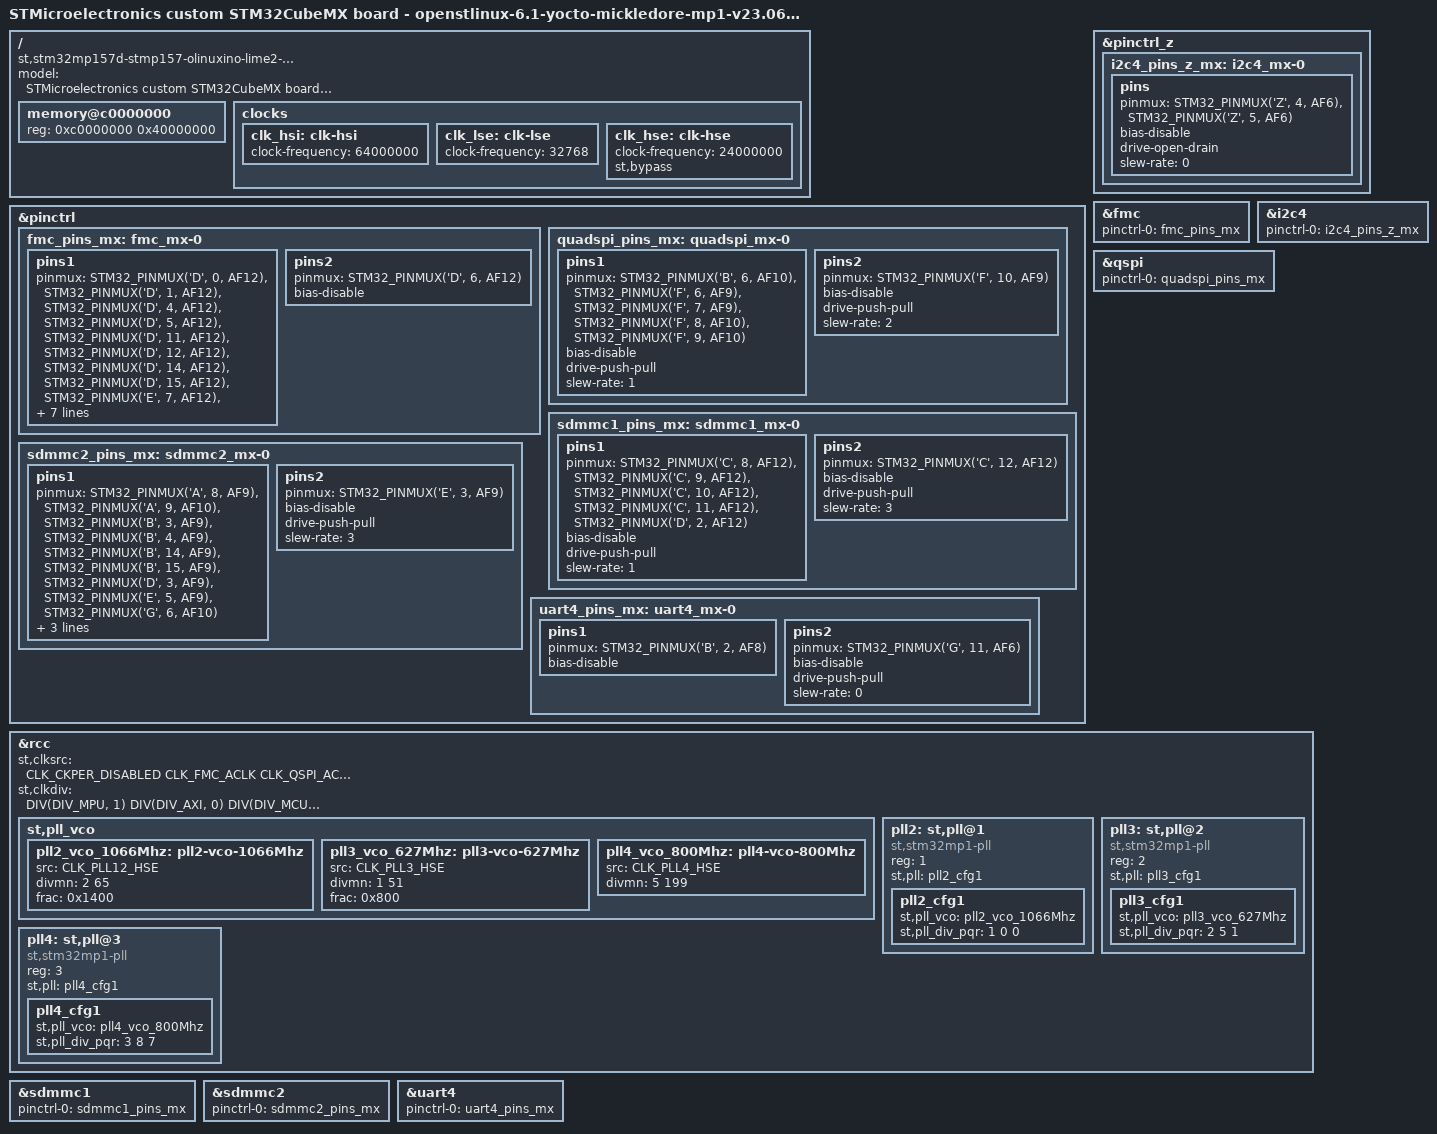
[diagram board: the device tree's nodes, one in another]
// SPDX-License-Identifier: (GPL-2.0-or-later OR BSD-3-Clause)
/*
 * Copyright (C) 2023, STMicroelectronics - All Rights Reserved
 * Author: STM32CubeMX code generation for STMicroelectronics.
 */

/* For more information on Device Tree configuration, please refer to
 * https://wiki.st.com/stm32mpu/wiki/Category:Device_tree_configuration
 */

/dts-v1/;
#include <dt-bindings/pinctrl/stm32-pinfunc.h>
#include <dt-bindings/clock/stm32mp1-clksrc.h>
#include "stm32mp15-mx.dtsi"

#include "stm32mp157.dtsi"
#include "stm32mp15xd.dtsi"
#include "stm32mp15-pinctrl.dtsi"
#include "stm32mp15xxaa-pinctrl.dtsi"
#include "stm32mp15-ddr.dtsi"

/* USER CODE BEGIN includes */
/* USER CODE END includes */

/ {
	model = "STMicroelectronics custom STM32CubeMX board - openstlinux-6.1-yocto-mickledore-mp1-v23.06.21";
	compatible = "st,stm32mp157d-stmp157-olinuxino-lime2-mx", "st,stm32mp157";

	memory@c0000000 {
		device_type = "memory";
		reg = <0xc0000000 0x40000000>;

		/* USER CODE BEGIN memory */
		/* USER CODE END memory */
	};

	/* USER CODE BEGIN root */
	/* USER CODE END root */

	clocks {
		/* USER CODE BEGIN clocks */
		/* USER CODE END clocks */

		clk_hsi: clk-hsi {
			clock-frequency = <64000000>;

			/* USER CODE BEGIN clk_hsi */
			/* USER CODE END clk_hsi */
		};
		clk_lse: clk-lse {
			clock-frequency = <32768>;

			/* USER CODE BEGIN clk_lse */
			/* USER CODE END clk_lse */
		};
		clk_hse: clk-hse {
			clock-frequency = <24000000>;
			st,bypass;

			/* USER CODE BEGIN clk_hse */
			/* USER CODE END clk_hse */
		};
	};

}; /*root*/

&pinctrl {
	fmc_pins_mx: fmc_mx-0 {
		pins1 {
			pinmux = <STM32_PINMUX('D', 0, AF12)>, /* FMC_D2 */
					 <STM32_PINMUX('D', 1, AF12)>, /* FMC_D3 */
					 <STM32_PINMUX('D', 4, AF12)>, /* FMC_NOE */
					 <STM32_PINMUX('D', 5, AF12)>, /* FMC_NWE */
					 <STM32_PINMUX('D', 11, AF12)>, /* FMC_CLE */
					 <STM32_PINMUX('D', 12, AF12)>, /* FMC_ALE */
					 <STM32_PINMUX('D', 14, AF12)>, /* FMC_D0 */
					 <STM32_PINMUX('D', 15, AF12)>, /* FMC_D1 */
					 <STM32_PINMUX('E', 7, AF12)>, /* FMC_D4 */
					 <STM32_PINMUX('E', 8, AF12)>, /* FMC_D5 */
					 <STM32_PINMUX('E', 9, AF12)>, /* FMC_D6 */
					 <STM32_PINMUX('E', 10, AF12)>, /* FMC_D7 */
					 <STM32_PINMUX('G', 9, AF12)>; /* FMC_NCE */
			bias-disable;
			drive-push-pull;
			slew-rate = <1>;
		};
		pins2 {
			pinmux = <STM32_PINMUX('D', 6, AF12)>; /* FMC_NWAIT */
			bias-disable;
		};
	};

	quadspi_pins_mx: quadspi_mx-0 {
		pins1 {
			pinmux = <STM32_PINMUX('B', 6, AF10)>, /* QUADSPI_BK1_NCS */
					 <STM32_PINMUX('F', 6, AF9)>, /* QUADSPI_BK1_IO3 */
					 <STM32_PINMUX('F', 7, AF9)>, /* QUADSPI_BK1_IO2 */
					 <STM32_PINMUX('F', 8, AF10)>, /* QUADSPI_BK1_IO0 */
					 <STM32_PINMUX('F', 9, AF10)>; /* QUADSPI_BK1_IO1 */
			bias-disable;
			drive-push-pull;
			slew-rate = <1>;
		};
		pins2 {
			pinmux = <STM32_PINMUX('F', 10, AF9)>; /* QUADSPI_CLK */
			bias-disable;
			drive-push-pull;
			slew-rate = <2>;
		};
	};

	sdmmc1_pins_mx: sdmmc1_mx-0 {
		pins1 {
			pinmux = <STM32_PINMUX('C', 8, AF12)>, /* SDMMC1_D0 */
					 <STM32_PINMUX('C', 9, AF12)>, /* SDMMC1_D1 */
					 <STM32_PINMUX('C', 10, AF12)>, /* SDMMC1_D2 */
					 <STM32_PINMUX('C', 11, AF12)>, /* SDMMC1_D3 */
					 <STM32_PINMUX('D', 2, AF12)>; /* SDMMC1_CMD */
			bias-disable;
			drive-push-pull;
			slew-rate = <1>;
		};
		pins2 {
			pinmux = <STM32_PINMUX('C', 12, AF12)>; /* SDMMC1_CK */
			bias-disable;
			drive-push-pull;
			slew-rate = <3>;
		};
	};

	sdmmc2_pins_mx: sdmmc2_mx-0 {
		pins1 {
			pinmux = <STM32_PINMUX('A', 8, AF9)>, /* SDMMC2_D4 */
					 <STM32_PINMUX('A', 9, AF10)>, /* SDMMC2_D5 */
					 <STM32_PINMUX('B', 3, AF9)>, /* SDMMC2_D2 */
					 <STM32_PINMUX('B', 4, AF9)>, /* SDMMC2_D3 */
					 <STM32_PINMUX('B', 14, AF9)>, /* SDMMC2_D0 */
					 <STM32_PINMUX('B', 15, AF9)>, /* SDMMC2_D1 */
					 <STM32_PINMUX('D', 3, AF9)>, /* SDMMC2_D7 */
					 <STM32_PINMUX('E', 5, AF9)>, /* SDMMC2_D6 */
					 <STM32_PINMUX('G', 6, AF10)>; /* SDMMC2_CMD */
			bias-disable;
			drive-push-pull;
			slew-rate = <1>;
		};
		pins2 {
			pinmux = <STM32_PINMUX('E', 3, AF9)>; /* SDMMC2_CK */
			bias-disable;
			drive-push-pull;
			slew-rate = <3>;
		};
	};

	uart4_pins_mx: uart4_mx-0 {
		pins1 {
			pinmux = <STM32_PINMUX('B', 2, AF8)>; /* UART4_RX */
			bias-disable;
		};
		pins2 {
			pinmux = <STM32_PINMUX('G', 11, AF6)>; /* UART4_TX */
			bias-disable;
			drive-push-pull;
			slew-rate = <0>;
		};
	};

	/* USER CODE BEGIN pinctrl */
	/* USER CODE END pinctrl */
};

&pinctrl_z {
	i2c4_pins_z_mx: i2c4_mx-0 {
		pins {
			pinmux = <STM32_PINMUX('Z', 4, AF6)>, /* I2C4_SCL */
					 <STM32_PINMUX('Z', 5, AF6)>; /* I2C4_SDA */
			bias-disable;
			drive-open-drain;
			slew-rate = <0>;
		};
	};

	/* USER CODE BEGIN pinctrl_z */
	/* USER CODE END pinctrl_z */
};

&fmc{
	pinctrl-names = "default";
	pinctrl-0 = <&fmc_pins_mx>;
	status = "okay";

	/* USER CODE BEGIN fmc */
	/* USER CODE END fmc */
};

&i2c4{
	pinctrl-names = "default";
	pinctrl-0 = <&i2c4_pins_z_mx>;
	status = "okay";

	/* USER CODE BEGIN i2c4 */
	/* USER CODE END i2c4 */
};

&qspi{
	pinctrl-names = "default";
	pinctrl-0 = <&quadspi_pins_mx>;
	status = "okay";

	/* USER CODE BEGIN qspi */
	/* USER CODE END qspi */
};

&rcc{
	status = "okay";

	/* USER CODE BEGIN rcc */
	/* USER CODE END rcc */

	st,clksrc = <
		CLK_CKPER_DISABLED
		CLK_FMC_ACLK
		CLK_QSPI_ACLK
		CLK_SDMMC12_PLL4P
		CLK_STGEN_HSI
		CLK_I2C46_PLL3Q
		CLK_UART24_PCLK1
		CLK_MPU_PLL1P
		CLK_AXI_PLL2P
		CLK_MCU_PLL3P
	>;
	st,clkdiv = <
		DIV(DIV_MPU, 1)
		DIV(DIV_AXI, 0)
		DIV(DIV_MCU, 0)
		DIV(DIV_APB1, 1)
		DIV(DIV_APB2, 1)
		DIV(DIV_APB3, 1)
		DIV(DIV_APB4, 1)
		DIV(DIV_APB5, 2)
		DIV(DIV_RTC, 0)
		DIV(DIV_MCO1, 0)
		DIV(DIV_MCO2, 0)
	>;
	st,pll_vco {
		pll2_vco_1066Mhz: pll2-vco-1066Mhz {
			src = < CLK_PLL12_HSE >;
			divmn = < 2 65 >;
			frac = < 0x1400 >;
		};
		pll3_vco_627Mhz: pll3-vco-627Mhz {
			src = < CLK_PLL3_HSE >;
			divmn = < 1 51 >;
			frac = < 0x800 >;
		};
		pll4_vco_800Mhz: pll4-vco-800Mhz {
			src = < CLK_PLL4_HSE >;
			divmn = < 5 199 >;
		};
		/* USER CODE BEGIN rcc_st-pll_vco */
		/* USER CODE END rcc_st-pll_vco */
	};

	pll2:st,pll@1 {
		compatible = "st,stm32mp1-pll";
		reg = <1>;

		st,pll = < &pll2_cfg1 >;

		pll2_cfg1: pll2_cfg1 {
			st,pll_vco = < &pll2_vco_1066Mhz >;
			st,pll_div_pqr = < 1 0 0 >;
		};
		/* USER CODE BEGIN pll2 */
		/* USER CODE END pll2 */
	};

	pll3:st,pll@2 {
		compatible = "st,stm32mp1-pll";
		reg = <2>;

		st,pll = < &pll3_cfg1 >;

		pll3_cfg1: pll3_cfg1 {
			st,pll_vco = < &pll3_vco_627Mhz >;
			st,pll_div_pqr = < 2 5 1 >;
		};
		/* USER CODE BEGIN pll3 */
		/* USER CODE END pll3 */
	};

	pll4:st,pll@3 {
		compatible = "st,stm32mp1-pll";
		reg = <3>;

		st,pll = < &pll4_cfg1 >;

		pll4_cfg1: pll4_cfg1 {
			st,pll_vco = < &pll4_vco_800Mhz >;
			st,pll_div_pqr = < 3 8 7 >;
		};
		/* USER CODE BEGIN pll4 */
		/* USER CODE END pll4 */
	};

};

&sdmmc1{
	pinctrl-names = "default";
	pinctrl-0 = <&sdmmc1_pins_mx>;
	status = "okay";

	/* USER CODE BEGIN sdmmc1 */
	/* USER CODE END sdmmc1 */
};

&sdmmc2{
	pinctrl-names = "default";
	pinctrl-0 = <&sdmmc2_pins_mx>;
	status = "okay";

	/* USER CODE BEGIN sdmmc2 */
	/* USER CODE END sdmmc2 */
};

&uart4{
	pinctrl-names = "default";
	pinctrl-0 = <&uart4_pins_mx>;
	status = "okay";

	/* USER CODE BEGIN uart4 */
	/* USER CODE END uart4 */
};

/* USER CODE BEGIN addons */
/* USER CODE END addons */

